AUTOSAR XML (schema 4-2-1)
package /VehicleProject
  system System
package /NM
  nm config NmConfig: can-nm-cluster-coupling=coupled-cluster=CAN00_CAN
    can nm cluster CAN00_CAN: communication-cluster=CAN00, nm-channel-id=0, nm-msg-cycle-time=0.1, nm-network-timeout=1, nm-repeat-message-time=0.4, nm-user-data-length=6, nm-wait-bus-sleep-time=0.75
      can nm node MyECU: controller=CT_CAN00, nm-if-ecu=MyECU_CAN, nm-node-id=0, nm-passive-mode-enabled=true, nm-msg-cycle-offset=0, nm-msg-reduced-time=0.05, nm-range-config={lower-can-id=1024, upper-can-id=1087}
      can nm node RearECU: nm-if-ecu=RearECU_CAN, nm-node-id=1, nm-passive-mode-enabled=true, nm-msg-cycle-offset=0, nm-msg-reduced-time=0.05, nm-range-config={lower-can-id=1024, upper-can-id=1087}
      can nm node Tester: nm-if-ecu=Tester_CAN, nm-node-id=0, nm-passive-mode-enabled=true, nm-msg-cycle-offset=0, nm-msg-reduced-time=0.05, nm-range-config={lower-can-id=1024, upper-can-id=1087}
    nm-if-ecus:
      nm ecu MyECU_CAN: ecu-instance=MyECU, nm-node-id-enabled=true, nm-passive-mode-enabled=true, nm-user-data-enabled=true
      nm ecu RearECU_CAN: nm-node-id-enabled=true, nm-passive-mode-enabled=true, nm-user-data-enabled=true
      nm ecu Tester_CAN: nm-node-id-enabled=true, nm-passive-mode-enabled=true, nm-user-data-enabled=true
package /Cluster
  can cluster CAN00: protocol-name=CAN
    can physical channel CHNL: comm-connectors=CN_CAN00
      frame BatteryStatus_oCAN00: id 0x102, to MyECU, frame-length=8, can-addressing-mode=STANDARD
        pdu BatteryStatus_oCAN00: length=8, minimum-delay=0, transmission-mode-false-timing=cyclic-timing={time-offset=0, time-period=0}, transmission-mode-true-timing=cyclic-timing={time-offset=0, time-period=0}, unused-bit-pattern=0
          signal rawCurrentData_oBatteryStatus_oCAN00: start 7, 16 bit, big-endian, init-value=32768, base-type=uint16, compu-method=CM_rawCurrentData, transfer-property=PENDING, to MyECU
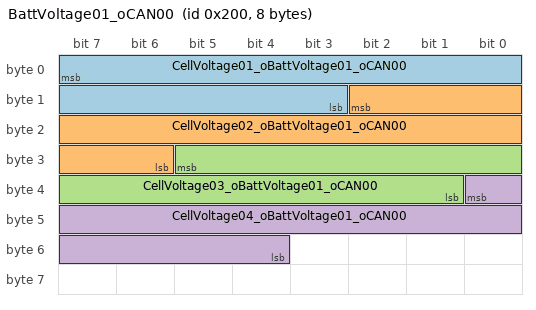
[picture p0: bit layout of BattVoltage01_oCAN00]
      frame BattVoltage01_oCAN00: id 0x200, from MyECU, frame-length=8, can-addressing-mode=STANDARD
        pdu BattVoltage01_oCAN00: length=8, minimum-delay=0, transmission-mode-false-timing=cyclic-timing={time-offset=0, time-period=0.1}, transmission-mode-true-timing=cyclic-timing={time-offset=0, time-period=0.1}, unused-bit-pattern=0
          signal CellVoltage01_oBattVoltage01_oCAN00: start 7, 13 bit, big-endian, init-value=0, base-type=uint16, data-constr=DC_CellVoltage01, transfer-property=PENDING
          signal CellVoltage02_oBattVoltage01_oCAN00: start 10, 13 bit, big-endian, init-value=0, base-type=uint16, data-constr=DC_CellVoltage02, transfer-property=PENDING
          signal CellVoltage03_oBattVoltage01_oCAN00: start 29, 13 bit, big-endian, init-value=0, base-type=uint16, data-constr=DC_CellVoltage03, transfer-property=PENDING
          signal CellVoltage04_oBattVoltage01_oCAN00: start 32, 13 bit, big-endian, init-value=0, base-type=uint16, data-constr=DC_CellVoltage04, transfer-property=PENDING
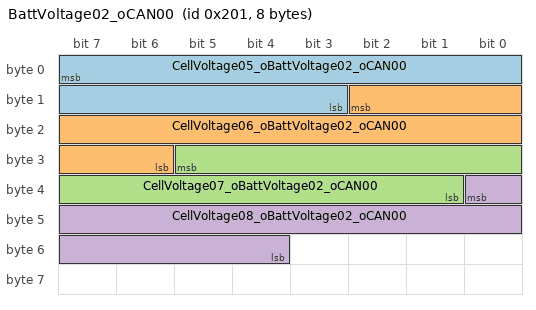
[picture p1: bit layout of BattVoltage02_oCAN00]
      frame BattVoltage02_oCAN00: id 0x201, from MyECU, frame-length=8, can-addressing-mode=STANDARD
        pdu BattVoltage02_oCAN00: length=8, minimum-delay=0, transmission-mode-false-timing=cyclic-timing={time-offset=0, time-period=0.1}, transmission-mode-true-timing=cyclic-timing={time-offset=0, time-period=0.1}, unused-bit-pattern=0
          signal CellVoltage05_oBattVoltage02_oCAN00: start 7, 13 bit, big-endian, init-value=0, base-type=uint16, data-constr=DC_CellVoltage05, transfer-property=PENDING
          signal CellVoltage06_oBattVoltage02_oCAN00: start 10, 13 bit, big-endian, init-value=0, base-type=uint16, data-constr=DC_CellVoltage06, transfer-property=PENDING
          signal CellVoltage07_oBattVoltage02_oCAN00: start 29, 13 bit, big-endian, init-value=0, base-type=uint16, data-constr=DC_CellVoltage07, transfer-property=PENDING
          signal CellVoltage08_oBattVoltage02_oCAN00: start 32, 13 bit, big-endian, init-value=0, base-type=uint16, data-constr=DC_CellVoltage08, transfer-property=PENDING
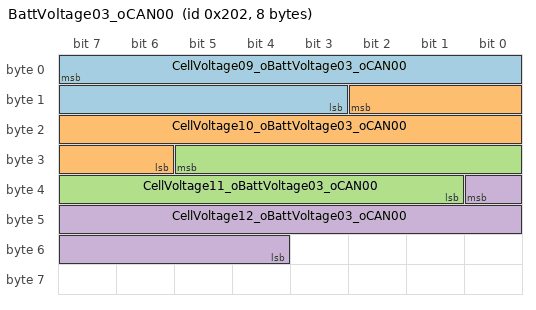
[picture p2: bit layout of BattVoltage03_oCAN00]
      frame BattVoltage03_oCAN00: id 0x202, from MyECU, frame-length=8, can-addressing-mode=STANDARD
        pdu BattVoltage03_oCAN00: length=8, minimum-delay=0, transmission-mode-false-timing=cyclic-timing={time-offset=0, time-period=0.1}, transmission-mode-true-timing=cyclic-timing={time-offset=0, time-period=0.1}, unused-bit-pattern=0
          signal CellVoltage09_oBattVoltage03_oCAN00: start 7, 13 bit, big-endian, init-value=0, base-type=uint16, data-constr=DC_CellVoltage09, transfer-property=PENDING
          signal CellVoltage10_oBattVoltage03_oCAN00: start 10, 13 bit, big-endian, init-value=0, base-type=uint16, data-constr=DC_CellVoltage10, transfer-property=PENDING
          signal CellVoltage11_oBattVoltage03_oCAN00: start 29, 13 bit, big-endian, init-value=0, base-type=uint16, data-constr=DC_CellVoltage11, transfer-property=PENDING
          signal CellVoltage12_oBattVoltage03_oCAN00: start 32, 13 bit, big-endian, init-value=0, base-type=uint16, data-constr=DC_CellVoltage12, transfer-property=PENDING
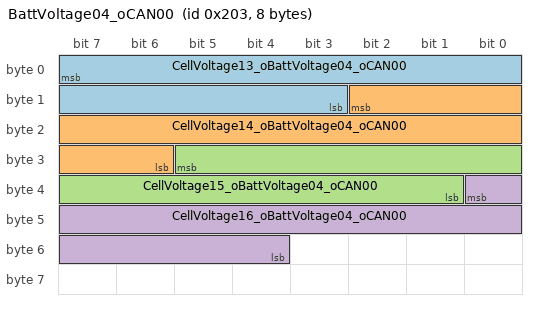
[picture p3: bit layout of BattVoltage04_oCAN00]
      frame BattVoltage04_oCAN00: id 0x203, from MyECU, frame-length=8, can-addressing-mode=STANDARD
        pdu BattVoltage04_oCAN00: length=8, minimum-delay=0, transmission-mode-false-timing=cyclic-timing={time-offset=0, time-period=0.1}, transmission-mode-true-timing=cyclic-timing={time-offset=0, time-period=0.1}, unused-bit-pattern=0
          signal CellVoltage13_oBattVoltage04_oCAN00: start 7, 13 bit, big-endian, init-value=0, base-type=uint16, data-constr=DC_CellVoltage13, transfer-property=PENDING
          signal CellVoltage14_oBattVoltage04_oCAN00: start 10, 13 bit, big-endian, init-value=0, base-type=uint16, data-constr=DC_CellVoltage14, transfer-property=PENDING
          signal CellVoltage15_oBattVoltage04_oCAN00: start 29, 13 bit, big-endian, init-value=0, base-type=uint16, data-constr=DC_CellVoltage15, transfer-property=PENDING
          signal CellVoltage16_oBattVoltage04_oCAN00: start 32, 13 bit, big-endian, init-value=0, base-type=uint16, data-constr=DC_CellVoltage16, transfer-property=PENDING
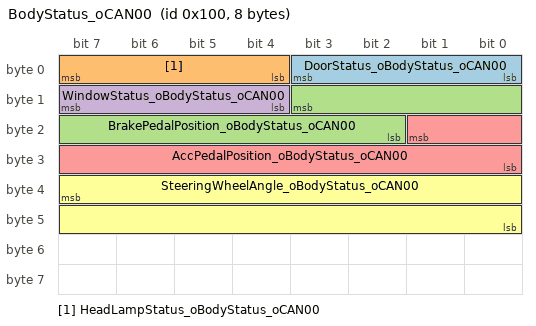
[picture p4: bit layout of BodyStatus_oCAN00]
      frame BodyStatus_oCAN00: id 0x100, to MyECU, frame-length=8, can-addressing-mode=STANDARD
        pdu BodyStatus_oCAN00: length=8, minimum-delay=0, transmission-mode-false-timing=cyclic-timing={time-offset=0, time-period=0.1}, transmission-mode-true-timing=cyclic-timing={time-offset=0, time-period=0.1}, unused-bit-pattern=0
          signal DoorStatus_oBodyStatus_oCAN00: start 3, 4 bit, big-endian, init-value=0, base-type=uint8, data-constr=DC_DoorStatus, transfer-property=PENDING, to MyECU
          signal HeadLampStatus_oBodyStatus_oCAN00: start 7, 4 bit, big-endian, init-value=0, base-type=uint8, data-constr=DC_HeadLampStatus, transfer-property=PENDING, to MyECU
          signal BrakePedalPosition_oBodyStatus_oCAN00: start 11, 10 bit, big-endian, init-value=0, base-type=uint16, compu-method=CM_BrakePedalPosition, transfer-property=PENDING, to MyECU
          signal WindowStatus_oBodyStatus_oCAN00: start 15, 4 bit, big-endian, init-value=0, base-type=uint8, data-constr=DC_WindowStatus, transfer-property=PENDING, to MyECU
          signal AccPedalPosition_oBodyStatus_oCAN00: start 17, 10 bit, big-endian, init-value=0, base-type=uint16, compu-method=CM_AccPedalPosition, transfer-property=PENDING, to MyECU
          signal SteeringWheelAngle_oBodyStatus_oCAN00: start 39, 16 bit, big-endian, init-value=0, base-type=sint16, compu-method=CM_SteeringWheelAngle, transfer-property=PENDING, to MyECU
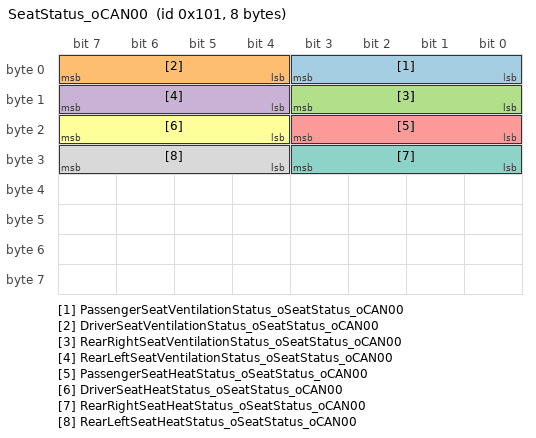
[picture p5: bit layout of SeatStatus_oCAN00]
      frame SeatStatus_oCAN00: id 0x101, from MyECU, frame-length=8, can-addressing-mode=STANDARD
        pdu SeatStatus_oCAN00: length=8, minimum-delay=0, transmission-mode-false-timing=cyclic-timing={time-offset=0, time-period=0.1}, transmission-mode-true-timing=cyclic-timing={time-offset=0, time-period=0.1}, unused-bit-pattern=0
          signal PassengerSeatVentilationStatus_oSeatStatus_oCAN00: start 3, 4 bit, big-endian, init-value=0, base-type=uint8, compu-method=CM_PassengerSeatVentilationStatus, data-constr=DC_PassengerSeatVentilationStatus, transfer-property=PENDING
          signal DriverSeatVentilationStatus_oSeatStatus_oCAN00: start 7, 4 bit, big-endian, init-value=0, base-type=uint8, compu-method=CM_DriverSeatVentilationStatus, data-constr=DC_DriverSeatVentilationStatus, transfer-property=PENDING
          signal RearRightSeatVentilationStatus_oSeatStatus_oCAN00: start 11, 4 bit, big-endian, init-value=0, base-type=uint8, compu-method=CM_RearRightSeatVentilationStatus, data-constr=DC_RearRightSeatVentilationStatus, transfer-property=PENDING
          signal RearLeftSeatVentilationStatus_oSeatStatus_oCAN00: start 15, 4 bit, big-endian, init-value=0, base-type=uint8, compu-method=CM_RearLeftSeatVentilationStatus, data-constr=DC_RearLeftSeatVentilationStatus, transfer-property=PENDING
          signal PassengerSeatHeatStatus_oSeatStatus_oCAN00: start 19, 4 bit, big-endian, init-value=0, base-type=uint8, compu-method=CM_PassengerSeatHeatStatus, data-constr=DC_PassengerSeatHeatStatus, transfer-property=PENDING
          signal DriverSeatHeatStatus_oSeatStatus_oCAN00: start 23, 4 bit, big-endian, init-value=0, base-type=uint8, compu-method=CM_DriverSeatHeatStatus, data-constr=DC_DriverSeatHeatStatus, transfer-property=PENDING
          signal RearRightSeatHeatStatus_oSeatStatus_oCAN00: start 27, 4 bit, big-endian, init-value=0, base-type=uint8, compu-method=CM_RearRightSeatHeatStatus, data-constr=DC_RearRightSeatHeatStatus, transfer-property=PENDING
          signal RearLeftSeatHeatStatus_oSeatStatus_oCAN00: start 31, 4 bit, big-endian, init-value=0, base-type=uint8, compu-method=CM_RearLeftSeatHeatStatus, data-constr=DC_RearLeftSeatHeatStatus, transfer-property=PENDING
package /ECU
  ecu instance MyECU: associated-com-i-pdu-group=[MyECU_oCAN00_Rx, MyECU_oCAN00_Tx]
    can communication controller CT_CAN00
    can communication connector CN_CAN00: comm-controller=CT_CAN00
package /IPDUGroup
  i signal i pdu group MyECU_oCAN00_Rx: communication-direction=IN, i-signal-i-pdus=[BatteryStatus_oCAN00, BodyStatus_oCAN00]
  i signal i pdu group MyECU_oCAN00_Tx: communication-direction=OUT, i-signal-i-pdus=[BattVoltage01_oCAN00, BattVoltage02_oCAN00, BattVoltage03_oCAN00, BattVoltage04_oCAN00, SeatStatus_oCAN00]
